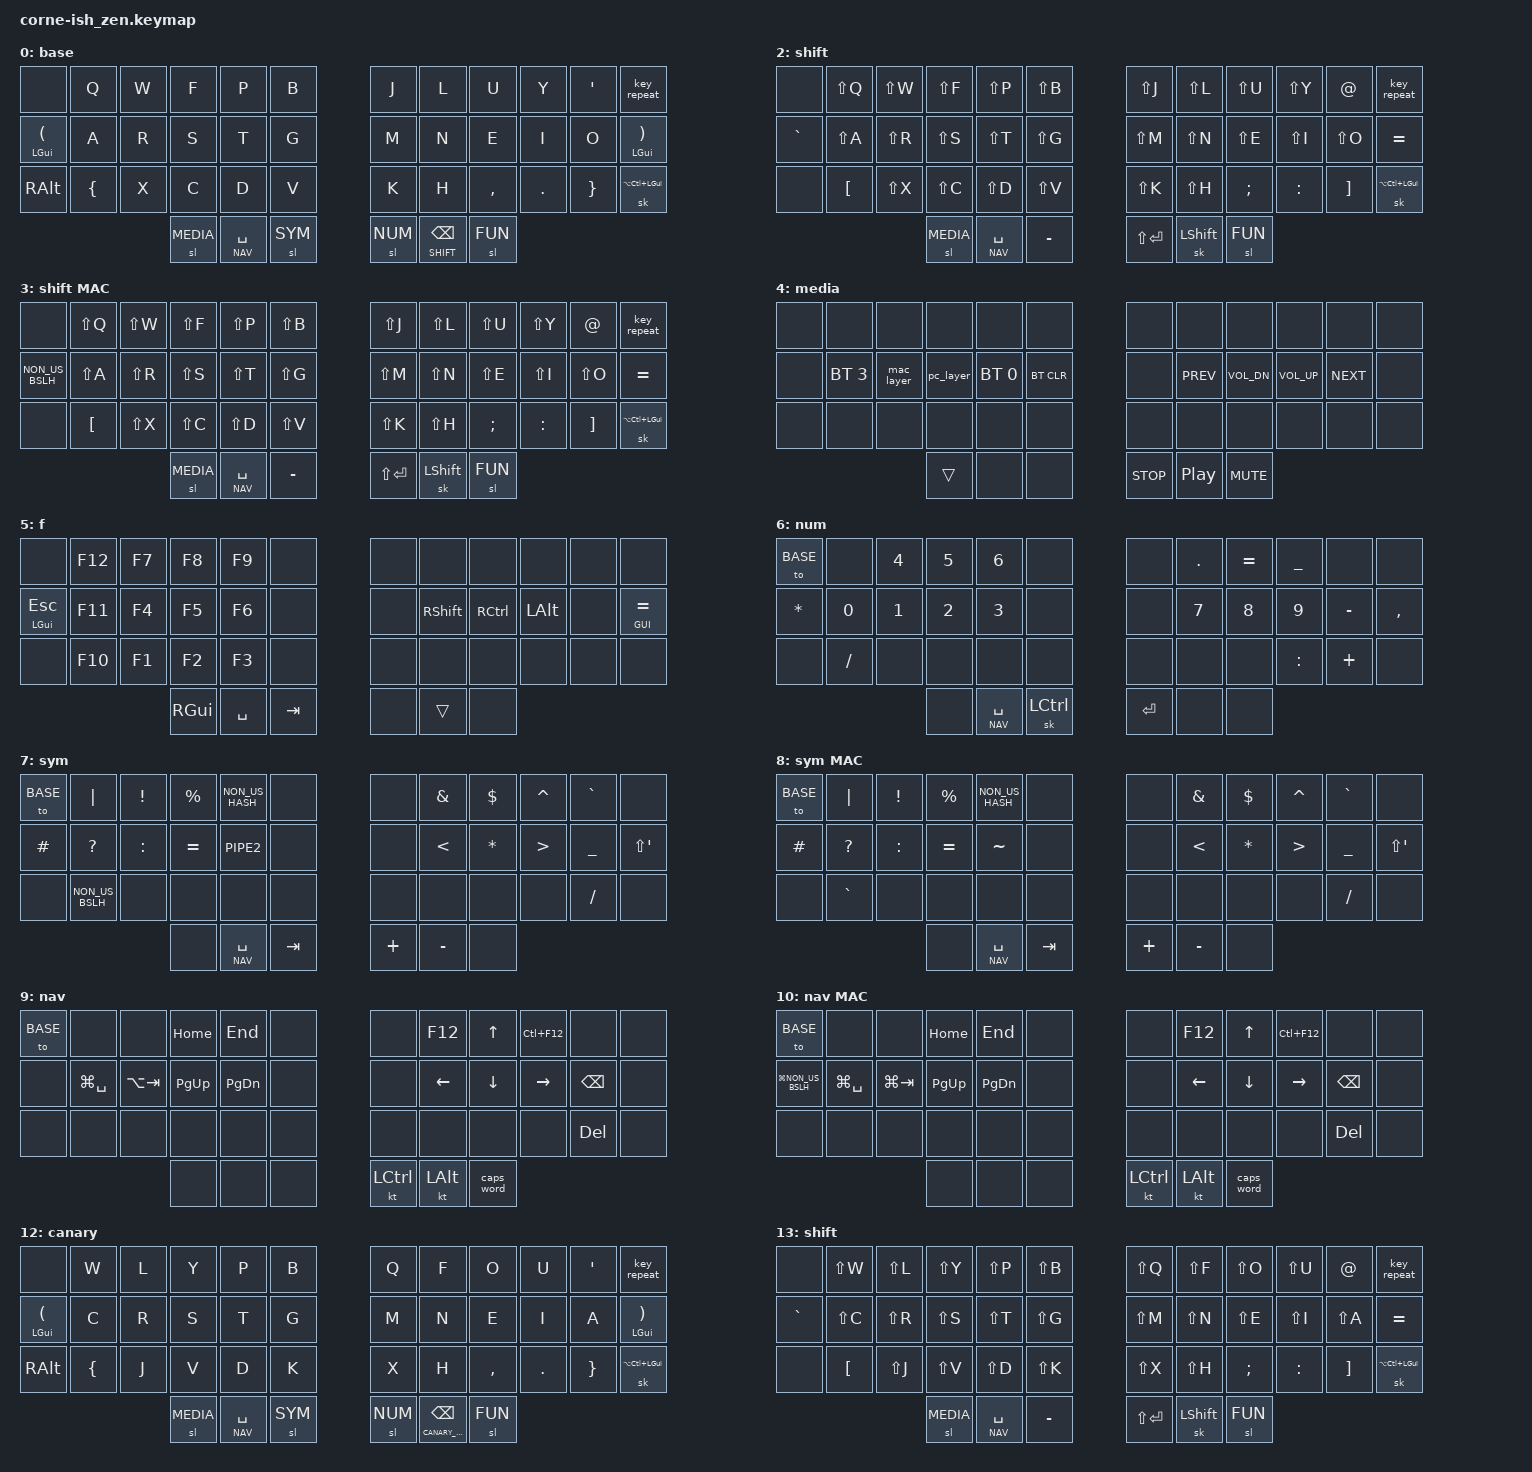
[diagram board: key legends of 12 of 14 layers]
/*
*
* Copyright (c) 2021 Darryl deHaan
* SPDX-License-Identifier: MIT
*
*/

#include <behaviors.dtsi>
#include <dt-bindings/zmk/keys.h>
#include <dt-bindings/zmk/bt.h>

#define BASE      0
#define BASE_MAC  1
#define SHIFT     2
#define SHIFT_MAC 3
#define MEDIA     4
#define FUN       5

#define NUM     6
#define SYM     7
#define SYM_MAC 8
#define NAV     9
#define NAV_MAC 10
#define FN      11

#define CANARY       12
#define CANARY_SHIFT 13

&caps_word {
    continue-list = <UNDERSCORE MINUS BACKSPACE N1 N2 N3 N4 N5 N6 N7 N8 N9 N0>;
};

/ {
    combos {        
        compatible = "zmk,combos"; 
        combo_z {            
            timeout-ms = <50>;            
            key-positions = <2 3>;
            layers = <0 1>;
            bindings = <&kp Z>;
        };
        combo_shift_z {            
            timeout-ms = <50>;            
            key-positions = <2 3 4>;
            layers = <0 1>;
            bindings = <&kp LS(Z)>;
        };
        combo_esc {
            timeout-ms = <50>;
            key-positions = <8 9>;
            bindings = <&kp ESC>;
        };
        combo_ctrl {
            timeout-ms = <50>;
            key-positions = <14 15 16>;
            bindings = <&sk LCTRL>;
        };
        combo_ctrl_shift {
            timeout-ms = <50>;
            key-positions = <13 14 15 16>;
            bindings = <&sk LS(LCTRL)>;
        };
        combo_alt {
            timeout-ms = <50>;
            key-positions = <19 20 21>;
            bindings = <&sk LALT>;
        };
        combo_alt_ctrl {
            timeout-ms = <50>;
            key-positions = <19 20 21 22>;
            bindings = <&sk LC(LALT)>;
        };
        combo_super_shift { 
            timeout-ms = <50>;
            key-positions = <12 23>;
            bindings = <&sk LS(LGUI)>;
        };
        combo_super_ctrl {
            timeout-ms = <50>;
            key-positions = <12 22>;
            bindings = <&sk LC(LGUI)>;
        };
        combo_to_canary {
            timeout-ms = <50>;
            key-positions = <36 41>;
            layers = <0>;
            bindings = <&to CANARY>;
        };
        combo_from_canary {
            timeout-ms = <50>;
            key-positions = <36 41>;
            layers = <8>;
            bindings = <&to BASE>;
        };
    };

    behaviors {
        td_colon: tap_dance_colon {
            compatible = "zmk,behavior-tap-dance";
            label = "TAP_DANCE_COLON";
            #binding-cells = <0>;
            tapping-term-ms = <350>;
            bindings = <&kp COLON>, <&kp SEMI>;
        };
        td_dot: tap_dance_dot {
            compatible = "zmk,behavior-tap-dance";
            label = "TAP_DANCE_DOT";
            #binding-cells = <0>;
            tapping-term-ms = <350>;
            bindings = <&kp DOT>, <&kp COMMA>;
        };
        td_quote: tap_dance_quote {
            compatible = "zmk,behavior-tap-dance";
            label = "TAP_DANCE_QUOTE";
            #binding-cells = <0>;
            tapping-term-ms = <350>;
            bindings = <&mt LGUI SQT>, <&kp AT>;
        };
        td_lpar: tap_dance_lpar {
            compatible = "zmk,behavior-tap-dance";
            label = "TAP_DANCE_LPAREN";
            #binding-cells = <0>;
            tapping-term-ms = <350>;
            bindings = <&kp LPAR>, <&kp LBRC>;
        };
        td_rpar: tap_dance_rpar {
            compatible = "zmk,behavior-tap-dance";
            label = "TAP_DANCE_RPAREN";
            #binding-cells = <0>;
            tapping-term-ms = <350>;
            bindings = <&kp RPAR>, <&kp RBRC>;
        };
        
        smod: special_mods {
            compatible = "zmk,behavior-hold-tap";
            label = "SPECIAL_MOD";
            #binding-cells = <2>;
            tapping-term-ms = <350>;
            quick-tap-ms = <180>;
            bindings = <&mo>, <&kp>;
            flavor = "tap-preferred";
        };
        smod_light: special_mods_light {
            compatible = "zmk,behavior-hold-tap";
            label = "SPECIAL_MOD_LIGHT";
            #binding-cells = <2>;
            tapping-term-ms = <250>;
            quick-tap-ms = <180>;
            bindings = <&mo>, <&kp>;
            flavor = "tap-preferred";
        };
        hmod: heavy_mods {
            compatible = "zmk,behavior-hold-tap";
            label = "HEAVY_MOD";
            #binding-cells = <2>;
            tapping-term-ms = <350>;
            quick-tap-ms = <0>;
            bindings = <&kp>, <&kp>;
            flavor = "tap-preferred";
        };
        bksp_hold: backspace_hold {
            compatible = "zmk,behavior-hold-tap";
            label = "BKSP HOLD";
            #binding-cells = <2>;
            tapping-term-ms = <200>;
            quick-tap-ms = <180>;
            bindings = <&mo>, <&kp>;
            flavor = "hold-preferred";
        };
    };

    macros {
        mac_layer: mac_layer {
            label = "mac";
            compatible = "zmk,behavior-macro";
            #binding-cells = <0>;
            bindings = <&bt BT_SEL 2>, <&to BASE_MAC>;
        };
        
        pc_layer: pc_layer {
            label = "pc";
            compatible = "zmk,behavior-macro";
            #binding-cells = <0>;
            bindings = <&bt BT_SEL 1>, <&to BASE>;
        };
    };

    keymap {
        compatible = "zmk,keymap";

        base_layer {
            label = "base";
            bindings = <
   &none           &kp Q    &kp W &kp F &kp P &kp B     &kp J &kp L  &kp U     &kp Y    &kp SQT  &key_repeat
   &hmod LGUI LPAR &kp A    &kp R &kp S &kp T &kp G     &kp M &kp N  &kp E     &kp I    &kp O    &hmod LGUI RPAR
   &kp RALT        &kp LBRC &kp X &kp C &kp D &kp V     &kp K &kp H  &kp COMMA &kp DOT  &kp RBRC &sk LA(LC(LGUI))
        &sl MEDIA &smod NAV SPACE &sl SYM     &sl NUM  &bksp_hold SHIFT BKSP &sl FUN
            >;
        };
        
        base_layer_mac {
            label = "base MAC";
            bindings = <
   &none           &kp Q    &kp W &kp F &kp P &kp B     &kp J &kp L  &kp U     &kp Y    &kp SQT  &key_repeat
   &hmod LGUI LPAR &kp A    &kp R &kp S &kp T &kp G     &kp M &kp N  &kp E     &kp I    &kp O    &hmod LGUI RPAR
   &smod RALT LC(LA(LG(LEFT)))         &kp LBRC &kp X &kp C &kp D &kp V     &kp K &kp H  &kp COMMA &kp DOT  &kp RBRC &sk LA(LC(LGUI))
        &sl MEDIA &smod NAV_MAC SPACE &sl SYM_MAC     &sl NUM  &bksp_hold SHIFT_MAC BKSP &sl FUN
            >;
        };
        
        shift_layer {
            label = "shift";
            bindings = <
   &none    &kp LS(Q) &kp LS(W) &kp LS(F) &kp LS(P) &kp LS(B)     &kp LS(J) &kp LS(L)  &kp LS(U) &kp LS(Y) &kp AT    &key_repeat
   &kp GRAV &kp LS(A) &kp LS(R) &kp LS(S) &kp LS(T) &kp LS(G)     &kp LS(M) &kp LS(N)  &kp LS(E) &kp LS(I) &kp LS(O) &kp EQUAL
   &none    &kp LBKT  &kp LS(X) &kp LS(C) &kp LS(D) &kp LS(V)     &kp LS(K) &kp LS(H)  &kp SEMI  &kp COLON &kp RBKT  &sk LA(LC(LGUI))
                    &sl MEDIA  &smod NAV SPACE &kp MINUS     &kp LS(RET) &sk LSHIFT &sl FUN
            >;
        };

        shift_layer_mac {
            label = "shift MAC";
            bindings = <
   &none    &kp LS(Q) &kp LS(W) &kp LS(F) &kp LS(P) &kp LS(B)     &kp LS(J) &kp LS(L)  &kp LS(U) &kp LS(Y) &kp AT    &key_repeat
   &kp NON_US_BSLH &kp LS(A) &kp LS(R) &kp LS(S) &kp LS(T) &kp LS(G)     &kp LS(M) &kp LS(N)  &kp LS(E) &kp LS(I) &kp LS(O) &kp EQUAL
   &none    &kp LBKT  &kp LS(X) &kp LS(C) &kp LS(D) &kp LS(V)     &kp LS(K) &kp LS(H)  &kp SEMI  &kp COLON &kp RBKT  &sk LA(LC(LGUI))
                    &sl MEDIA  &smod NAV SPACE &kp MINUS     &kp LS(RET) &sk LSHIFT &sl FUN
            >;
        };

        media_layer {
            label = "media";
            bindings = <
    &none &none &none        &none        &none      &none       &none &none      &none        &none        &none       &none
    &none &bt BT_SEL 3 &mac_layer &pc_layer &bt BT_SEL 0 &bt BT_CLR  &none &kp C_PREV &kp C_VOL_DN &kp C_VOL_UP &kp C_NEXT  &none
    &none &none &none        &none        &none      &none       &none &none      &none        &none        &none       &none
                                        &trans &none &none       &kp C_STOP &kp C_PLAY_PAUSE &kp C_MUTE
            >;
        };

        fun_layer {
            label = "f";
            bindings = <
    &none        &kp F12 &kp F7 &kp F8 &kp F9 &none    &none &none      &none     &none    &none &none
    &mt LGUI ESC &kp F11 &kp F4 &kp F5 &kp F6 &none   &none &kp RSHIFT &kp RCTRL &kp LALT &none &mt GUI EQUAL
    &none        &kp F10 &kp F1 &kp F2 &kp F3 &none    &none &none      &none     &none    &none &none
                                &kp RGUI &kp SPACE &kp TAB                  &none &trans &none
            >;
        };


        num {
            label = "num";
            bindings = <
    &to BASE  &none    &kp N4 &kp N5 &kp N6 &none         &none &kp DOT &kp EQUAL &kp UNDERSCORE  &none     &none
    &kp ASTRK &kp N0   &kp N1 &kp N2 &kp N3 &none         &none &kp N7  &kp N8    &kp N9          &kp MINUS &kp COMMA
    &none     &kp FSLH &none  &none  &none  &none         &none &none   &none     &kp COLON       &kp PLUS  &none
       &none &smod_light NAV SPACE &sk LCTRL         &kp RET &none &none
            >;
        };

        sym {
            label = "sym";
            bindings = <
    &to BASE &kp PIPE        &kp EXCL  &kp PERCENT  &kp NON_US_HASH &none         &none &kp AMPS &kp DOLLAR &kp CARET &kp GRAV       &none
    &kp HASH &kp QUESTION    &kp COLON &kp EQUAL    &kp PIPE2       &none         &none &kp LT   &kp ASTRK  &kp GT    &kp UNDERSCORE &kp LS(SQT)
    &none    &kp NON_US_BSLH &none     &none        &none           &none         &none &none    &none      &none     &kp FSLH       &none
                                  &none &smod NAV SPACE &kp TAB         &kp PLUS &kp MINUS &none
            >;
        };

        sym_mac {
            label = "sym MAC";
            bindings = <
    &to BASE &kp PIPE        &kp EXCL  &kp PERCENT  &kp NON_US_HASH &none         &none &kp AMPS &kp DOLLAR &kp CARET &kp GRAV       &none
    &kp HASH &kp QUESTION    &kp COLON &kp EQUAL    &kp TILDE       &none         &none &kp LT   &kp ASTRK  &kp GT    &kp UNDERSCORE &kp LS(SQT)
    &none    &kp GRAV        &none     &none        &none           &none         &none &none    &none      &none     &kp FSLH       &none
                                  &none &smod NAV SPACE &kp TAB         &kp PLUS &kp MINUS &none
            >;
        };

        nav {
            label = "nav";
            bindings = <
    &to BASE &none         &none       &kp HOME  &kp END   &none         &none &kp F12  &kp UP   &kp LC(F12) &none    &none
    &none    &kp LG(SPACE) &kp LA(TAB) &kp PG_UP &kp PG_DN &none         &none &kp LEFT &kp DOWN &kp RIGHT   &kp BKSP &none
    &none    &none         &none       &none     &none     &none         &none &none    &none    &none       &kp DEL  &none
                                               &none &none &none         &kt LCTRL &kt LALT &caps_word
            >;
        };
        
        nav_mac {
            label = "nav MAC";
            bindings = <
    &to BASE &none      &none       &kp HOME  &kp END   &none         &none &kp F12  &kp UP   &kp LC(F12) &none    &none
    &kp LG(NON_US_BSLH) &kp LG(SPACE) &kp LG(TAB) &kp PG_UP &kp PG_DN &none         &none &kp LEFT &kp DOWN &kp RIGHT   &kp BKSP &none
    &none    &none      &none       &none     &none     &none         &none &none    &none    &none       &kp DEL  &none
                                               &none &none &none         &kt LCTRL &kt LALT &caps_word
            >;
        };
        
        fn {
            label = "fn";
            bindings = <
    &none &none &kp F5  &kp F8 &none   &none    &none &none       &none &none &none &none
    &none &none &kp F10 &kp F2 &kp F12 &none    &none &kp LC(LA(LG(0))) &kp LC(LA(LG(1))) &kp LC(LA(LG(3))) &none &none
    &none &none &none   &none  &none   &none    &none &none       &none &none &none &none
      &none &smod_light NAV SPACE &none    &none &trans &none
            >;
        };

        canary {
            label = "canary";
            bindings = <
   &none           &kp W    &kp L &kp Y &kp P &kp B     &kp Q &kp F  &kp O     &kp U    &kp SQT  &key_repeat
   &hmod LGUI LPAR &kp C    &kp R &kp S &kp T &kp G     &kp M &kp N  &kp E     &kp I    &kp A    &hmod LGUI RPAR
   &kp RALT        &kp LBRC &kp J &kp V &kp D &kp K     &kp X &kp H  &kp COMMA &kp DOT  &kp RBRC &sk LA(LC(LGUI))
        &sl MEDIA &smod NAV SPACE &sl SYM     &sl NUM  &bksp_hold CANARY_SHIFT BKSP &sl FUN
            >;
        };
        
        canary_layer {
            label = "shift";
            bindings = <
   &none    &kp LS(W) &kp LS(L) &kp LS(Y) &kp LS(P) &kp LS(B)     &kp LS(Q) &kp LS(F)  &kp LS(O) &kp LS(U) &kp AT    &key_repeat
   &kp GRAV &kp LS(C) &kp LS(R) &kp LS(S) &kp LS(T) &kp LS(G)     &kp LS(M) &kp LS(N)  &kp LS(E) &kp LS(I) &kp LS(A) &kp EQUAL
   &none    &kp LBKT  &kp LS(J) &kp LS(V) &kp LS(D) &kp LS(K)     &kp LS(X) &kp LS(H)  &kp SEMI  &kp COLON &kp RBKT  &sk LA(LC(LGUI))
                    &sl MEDIA  &smod NAV SPACE &kp MINUS     &kp LS(RET) &sk LSHIFT &sl FUN
            >;
        };
        
    };
};
